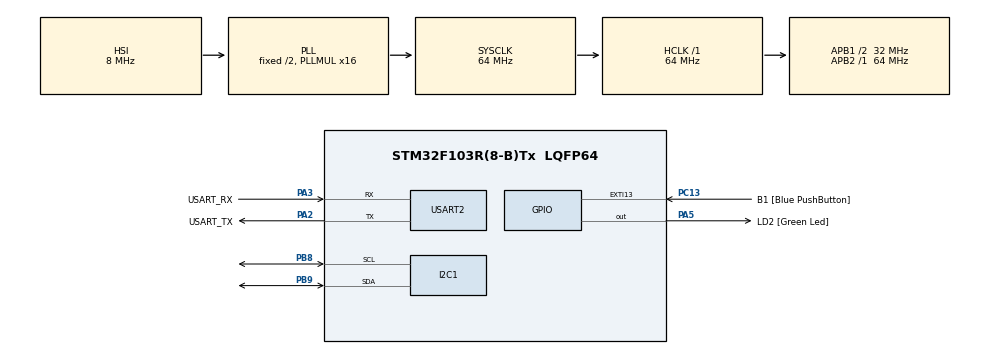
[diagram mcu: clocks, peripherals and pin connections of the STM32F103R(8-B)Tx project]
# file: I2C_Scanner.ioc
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Mcu.Family=STM32F1
Dma.I2C1_TX.1.PeriphDataAlignment=DMA_PDATAALIGN_BYTE
PC15-OSC32_OUT.Mode=LSE-External-Oscillator
NVIC.DMA1_Channel6_IRQn=true\:0\:0\:false\:false\:true\:false\:true
PA2.GPIO_PuPd=GPIO_NOPULL
Dma.I2C1_RX.0.PeriphInc=DMA_PINC_DISABLE
Dma.I2C1_RX.0.MemDataAlignment=DMA_MDATAALIGN_BYTE
PD1-OSC_OUT.Mode=HSE-External-Clock-Source
NVIC.I2C1_EV_IRQn=true\:0\:0\:false\:false\:true\:true\:true
Dma.I2C1_TX.1.Mode=DMA_NORMAL
PA14.GPIO_Label=TCK
PA3.GPIO_PuPd=GPIO_NOPULL
PA2.GPIO_Speed=GPIO_SPEED_FREQ_LOW
PC13-TAMPER-RTC.Signal=GPXTI13
PD0-OSC_IN.Signal=RCC_OSC_IN
RCC.APB1CLKDivider=RCC_HCLK_DIV2
PC14-OSC32_IN.Signal=RCC_OSC32_IN
PA3.GPIO_Speed=GPIO_SPEED_FREQ_LOW
RCC.SYSCLKSource=RCC_SYSCLKSOURCE_PLLCLK
ProjectManager.StackSize=0x400
PD1-OSC_OUT.Signal=RCC_OSC_OUT
Dma.I2C1_TX.1.Direction=DMA_MEMORY_TO_PERIPH
PA3.Mode=Asynchronous
PA13.Signal=SYS_JTMS-SWDIO
ProjectManager.TargetToolchain=STM32CubeIDE
I2C1.I2C_Mode=I2C_Fast
PA3.GPIO_Mode=GPIO_MODE_AF_PP
RCC.HCLKFreq_Value=64000000
PB9.Mode=I2C
RCC.APB2TimFreq_Value=64000000
Dma.I2C1_RX.0.MemInc=DMA_MINC_ENABLE
Dma.I2C1_TX.1.Instance=DMA1_Channel6
Dma.I2C1_RX.0.PeriphDataAlignment=DMA_PDATAALIGN_BYTE
Dma.I2C1_TX.1.PeriphInc=DMA_PINC_DISABLE
RCC.USBFreq_Value=64000000
PC15-OSC32_OUT.Signal=RCC_OSC32_OUT
RCC.AHBFreq_Value=64000000
PD0-OSC_IN.Mode=HSE-External-Clock-Source
Dma.I2C1_RX.0.Priority=DMA_PRIORITY_LOW
NVIC.EXTI15_10_IRQn=true\:0\:0\:false\:false\:true\:true\:true
PA5.Signal=GPIO_Output
board=NUCLEO-F103RB
Dma.I2C1_RX.0.Mode=DMA_NORMAL
Dma.I2C1_TX.1.Priority=DMA_PRIORITY_LOW
RCC.RTCClockSelection=RCC_RTCCLKSOURCE_LSE
PC13-TAMPER-RTC.GPIO_Label=B1 [Blue PushButton]
RCC.PLLMUL=RCC_PLL_MUL16
RCC.APB2Freq_Value=64000000
PC14-OSC32_IN.Mode=LSE-External-Oscillator
PA5.GPIO_ModeDefaultOutputPP=GPIO_MODE_OUTPUT_PP
PA14.Mode=Serial_Wire
Dma.I2C1_TX.1.MemInc=DMA_MINC_ENABLE
PA5.GPIO_PuPd=GPIO_NOPULL
Dma.I2C1_TX.1.MemDataAlignment=DMA_MDATAALIGN_BYTE
Dma.I2C1_RX.0.Direction=DMA_PERIPH_TO_MEMORY
PA13.Mode=Serial_Wire
NVIC.I2C1_ER_IRQn=true\:0\:0\:false\:false\:true\:true\:true
Mcu.Name=STM32F103R(8-B)Tx
PA2.Signal=USART2_TX
PA13.GPIO_Label=TMS
PB3.Signal=SYS_JTDO-TRACESWO
RCC.SYSCLKFreq_VALUE=64000000
Mcu.Package=LQFP64
PB9.Signal=I2C1_SDA
PA5.GPIO_Label=LD2 [Green Led]
USART2.VirtualMode=VM_ASYNC
PC13-TAMPER-RTC.GPIO_PuPd=GPIO_NOPULL
PA2.GPIO_Label=USART_TX
PA14.Signal=SYS_JTCK-SWCLK
ProjectManager.HeapSize=0x200
PA5.GPIO_Speed=GPIO_SPEED_FREQ_LOW
NVIC.PriorityGroup=NVIC_PRIORITYGROUP_4
PB8.Mode=I2C
Dma.Request1=I2C1_TX
RCC.APB1TimFreq_Value=64000000
PA2.Mode=Asynchronous
PB8.Signal=I2C1_SCL
NVIC.DMA1_Channel7_IRQn=true\:0\:0\:false\:false\:true\:false\:true
Dma.Request0=I2C1_RX
RCC.APB1Freq_Value=32000000
Dma.I2C1_RX.0.Instance=DMA1_Channel7
PA3.GPIO_Label=USART_RX
PA3.Signal=USART2_RX
PA2.GPIO_Mode=GPIO_MODE_AF_PP
PB3.GPIO_Label=SWO

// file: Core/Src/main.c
/* USER CODE BEGIN Header */
/**
  ******************************************************************************
  * @file           : main.c
  * @brief          : Main program body
  ******************************************************************************
  * @attention
  *
  * <h2><center>&copy; Copyright (c) 2021 STMicroelectronics.
  * All rights reserved.</center></h2>
  *
  * This software component is licensed by ST under BSD 3-Clause license,
  * the "License"; You may not use this file except in compliance with the
  * License. You may obtain a copy of the License at:
  *                        opensource.org/licenses/BSD-3-Clause
  *
  ******************************************************************************
  */
/* USER CODE END Header */
#include "main.h"
#include "dma.h"
#include "i2c.h"
#include "usart.h"
#include "gpio.h"

void SystemClock_Config(void);

int main(void)
{

  /* MCU Configuration--------------------------------------------------------*/

  /* Reset of all peripherals, Initializes the Flash interface and the Systick. */
  HAL_Init();

  /* Configure the system clock */
  SystemClock_Config();

  /* Initialize all configured peripherals */
  MX_GPIO_Init();
  MX_DMA_Init();
  MX_USART2_UART_Init();
  MX_I2C1_Init();
  /* USER CODE BEGIN 2 */
//I2C1 Scanner

  	HAL_StatusTypeDef result;
   	uint8_t i;
   	for (i=1; i<128; i++)
   	{
   	  result = HAL_I2C_IsDeviceReady(&hi2c1, (uint16_t)(i<<1), 2, 2);
   	  if (result != HAL_OK) // HAL_ERROR or HAL_BUSY or HAL_TIMEOUT
   	  {
   		 //not found on the addres
   	  }
   	  if (result == HAL_OK)
   	  {
   		 //device found -- put break point for example
   	  }
   	}

  /* USER CODE END 2 */

  /* Infinite loop */
  while (1)
  {

  }
}

void SystemClock_Config(void)
{
  RCC_OscInitTypeDef RCC_OscInitStruct = {0};
  RCC_ClkInitTypeDef RCC_ClkInitStruct = {0};

  /** Initializes the RCC Oscillators according to the specified parameters
  * in the RCC_OscInitTypeDef structure.
  */
  RCC_OscInitStruct.OscillatorType = RCC_OSCILLATORTYPE_HSI;
  RCC_OscInitStruct.HSIState = RCC_HSI_ON;
  RCC_OscInitStruct.HSICalibrationValue = RCC_HSICALIBRATION_DEFAULT;
  RCC_OscInitStruct.PLL.PLLState = RCC_PLL_ON;
  RCC_OscInitStruct.PLL.PLLSource = RCC_PLLSOURCE_HSI_DIV2;
  RCC_OscInitStruct.PLL.PLLMUL = RCC_PLL_MUL16;
  if (HAL_RCC_OscConfig(&RCC_OscInitStruct) != HAL_OK)
  {
    Error_Handler();
  }
  /** Initializes the CPU, AHB and APB buses clocks
  */
  RCC_ClkInitStruct.ClockType = RCC_CLOCKTYPE_HCLK|RCC_CLOCKTYPE_SYSCLK
                              |RCC_CLOCKTYPE_PCLK1|RCC_CLOCKTYPE_PCLK2;
  RCC_ClkInitStruct.SYSCLKSource = RCC_SYSCLKSOURCE_PLLCLK;
  RCC_ClkInitStruct.AHBCLKDivider = RCC_SYSCLK_DIV1;
  RCC_ClkInitStruct.APB1CLKDivider = RCC_HCLK_DIV2;
  RCC_ClkInitStruct.APB2CLKDivider = RCC_HCLK_DIV1;

  if (HAL_RCC_ClockConfig(&RCC_ClkInitStruct, FLASH_LATENCY_2) != HAL_OK)
  {
    Error_Handler();
  }
}

void Error_Handler(void)
{
  __disable_irq();
  while (1)
  {
  }
}

/************************ (C) COPYRIGHT STMicroelectronics *****END OF FILE****/
